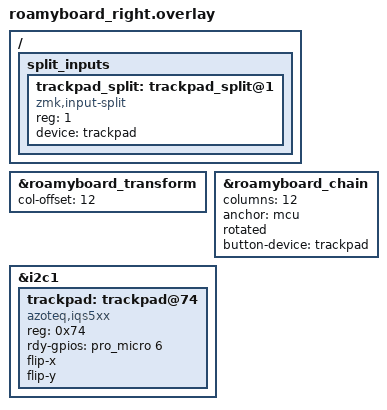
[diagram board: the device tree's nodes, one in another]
/*
 * Right half of a split roamyboard, the peripheral: keymap columns 12 to 23.
 * The half is the left half's hardware turned by 180 degrees, so its MCU module
 * sits at its left (inner) end and columns fill outward from it.
 *
 * SPDX-License-Identifier: MIT
 */

#include <roamyboard.dtsi>

&roamyboard_transform {
    col-offset = <12>;
};

&roamyboard_chain {
    columns = <12>;
    anchor = "mcu";
    rotated;
    button-device = <&trackpad>; // the buttons share the trackpad's input split
};

// The pointing module's trackpad. RDY floats while no pointing module is attached.
&i2c1 {
    trackpad: trackpad@74 {
        compatible = "azoteq,iqs5xx";
        reg = <0x74>;
        rdy-gpios = <&pro_micro 6 (GPIO_ACTIVE_HIGH | GPIO_PULL_DOWN)>; // D6, P1.00
        // The pointing module holds the pad turned by 180 degrees on this half.
        flip-x;
        flip-y;
    };
};

/ {
    // Sends the trackpad's input events, the pointing module's buttons among them, to the
    // central, which reports them to the host.
    split_inputs {
        #address-cells = <1>;
        #size-cells = <0>;

        trackpad_split: trackpad_split@1 {
            compatible = "zmk,input-split";
            reg = <1>;
            device = <&trackpad>;
        };

    };
};
